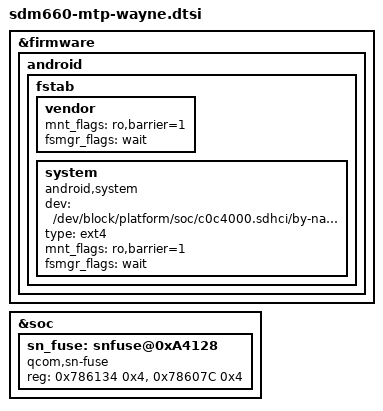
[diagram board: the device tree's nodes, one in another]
#include "wayne-common-base.dtsi"

/* sdm660.dtsi wayne specific diff */
&firmware {
	android {
		/delete-node/ vbmeta;
		fstab {
			vendor {
				mnt_flags = "ro,barrier=1";
				fsmgr_flags = "wait";
			};

			system {
				compatible = "android,system";
				dev = "/dev/block/platform/soc/c0c4000.sdhci/by-name/system";
				type = "ext4";
				mnt_flags = "ro,barrier=1";
				fsmgr_flags = "wait";
				status = "ok";
			};
		};
	};
};

&soc {
	sn_fuse: snfuse@0xA4128 {
		compatible = "qcom,sn-fuse";
		reg = <0x786134 0x4>,
			<0x78607C 0x4>;
		reg-names = "sn-base","fuse-state";
	};
};
